# MC1322x register map
Registers are 32-bit, access not given, no defined reset value unless marked. A register's access mark holds for its fields unless they carry their own. Addresses are absolute; registers are grouped by the start of their names; [hi:lo] are bit positions; {n}, {i} and the like mark numbered series.

## TMR3
0x80007060 TMR3_COMPARISON_VALUE_1_[60]_<15:0> 16-bit
0x80007062 TMR3_COMPARISON_VALUE_2_[62]_<15:0> 16-bit
0x80007064 TMR3_CAPTURE_VALUE_[64]_<15:0> 16-bit
0x80007066 TMR3_LOAD_VALUE_[66]_<15:0> 16-bit
0x80007068 TMR3_HOLD_VALUE_[68]_<15:0> 16-bit
0x8000706A TMR3_COUNTER_[6A]_<15:0> 16-bit
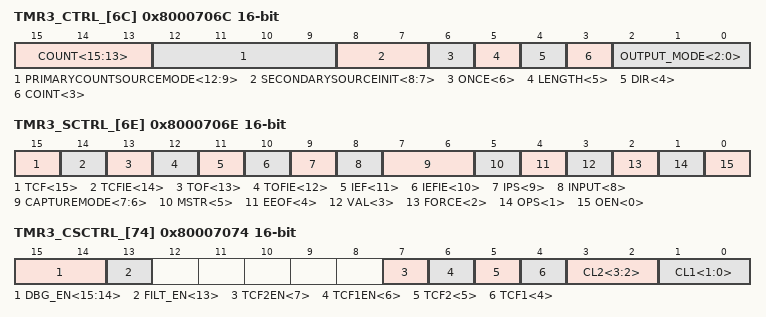
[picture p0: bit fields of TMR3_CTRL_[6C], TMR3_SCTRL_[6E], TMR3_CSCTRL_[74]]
0x8000706C TMR3_CTRL_[6C] 16-bit
  [15:13] COUNT<15:13>, [12:9] PRIMARYCOUNTSOURCEMODE<12:9>, [8:7] SECONDARYSOURCEINIT<8:7>, [6] ONCE<6>, [5] LENGTH<5>, [4] DIR<4>, [3] COINT<3>, [2:0] OUTPUT_MODE<2:0>
0x8000706E TMR3_SCTRL_[6E] 16-bit
  [15] TCF<15>, [14] TCFIE<14>, [13] TOF<13>, [12] TOFIE<12>, [11] IEF<11>, [10] IEFIE<10>, [9] IPS<9>, [8] INPUT<8>, [7:6] CAPTUREMODE<7:6>, [5] MSTR<5>, [4] EEOF<4>, [3] VAL<3>, [2] FORCE<2>, [1] OPS<1>, [0] OEN<0>
0x80007070 TMR3_COMPARATOR_LOAD_1_[70]_<15:0> 16-bit
0x80007072 TMR3_COMPARATOR_LOAD_2_[72]_<15:0> 16-bit
0x80007074 TMR3_CSCTRL_[74] 16-bit
  [15:14] DBG_EN<15:14>, [13] FILT_EN<13>, [7] TCF2EN<7>, [6] TCF1EN<6>, [5] TCF2<5>, [4] TCF1<4>, [3:2] CL2<3:2>, [1:0] CL1<1:0>

## ASM
{0x80008000+4i} ASM_KEY{i}_[{4i:02}] (i=0..2)
0x8000800C ASM_KEY3_[0C]
{0x80008010+4i} ASM_DATA{i}_[{4i+10}] (i=0..2)
0x8000801C ASM_DATA3_[1C]
{0x80008020+4i} ASM_CTR{i}_[{4i+20}] (i=0..2)
0x8000802C ASM_CTR3_[2C]
{0x80008030+4i} ASM_CTR_RSLT_{i}_[{4i+30}] (i=0..2)
0x8000803C ASM_CTR_RSLT_3_[3C]
{0x80008040+4i} ASM_CBC_RSLT_{i}_[{4i+40}] (i=0..2)
0x8000804C ASM_CBC_RSLT_3_[4C]
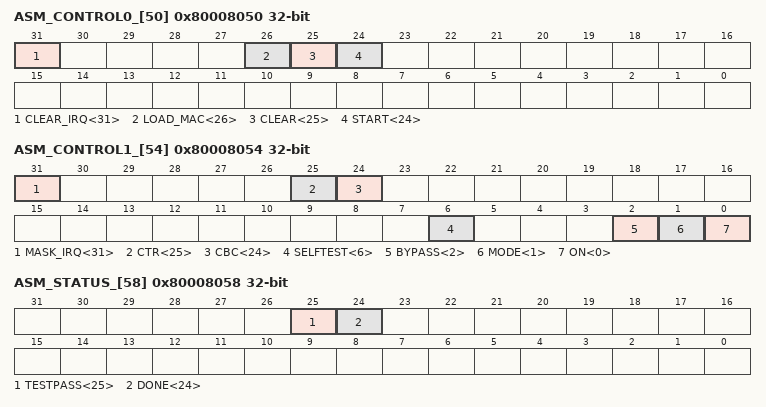
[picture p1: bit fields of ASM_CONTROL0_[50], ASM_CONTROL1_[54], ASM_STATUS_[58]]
0x80008050 ASM_CONTROL0_[50]
  [31] CLEAR_IRQ<31>, [26] LOAD_MAC<26>, [25] CLEAR<25>, [24] START<24>
0x80008054 ASM_CONTROL1_[54]
  [31] MASK_IRQ<31>, [25] CTR<25>, [24] CBC<24>, [6] SELFTEST<6>, [2] BYPASS<2>, [1] MODE<1>, [0] ON<0>
0x80008058 ASM_STATUS_[58]
  [25] TESTPASS<25>, [24] DONE<24>
{0x80008060+4i} ASM_MAC{i}_[{4i+60}] (i=0..2)
0x8000806C ASM_MAC3_[6C]

## UART2
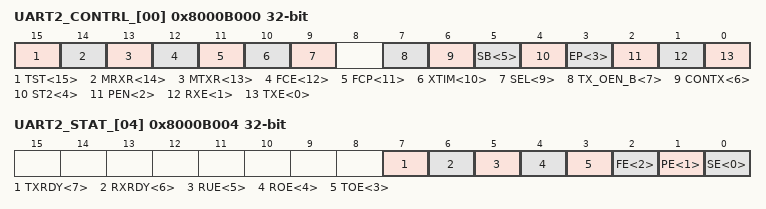
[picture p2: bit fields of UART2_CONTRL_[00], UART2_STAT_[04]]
0x8000B000 UART2_CONTRL_[00]
  [15] TST<15>, [14] MRXR<14>, [13] MTXR<13>, [12] FCE<12>, [11] FCP<11>, [10] XTIM<10>, [9] SEL<9>, [7] TX_OEN_B<7>, [6] CONTX<6>, [5] SB<5>, [4] ST2<4>, [3] EP<3>, [2] PEN<2>, [1] RXE<1>, [0] TXE<0>
0x8000B004 UART2_STAT_[04]
  [7] TXRDY<7>, [6] RXRDY<6>, [5] RUE<5>, [4] ROE<4>, [3] TOE<3>, [2] FE<2>, [1] PE<1>, [0] SE<0>
0x8000B008 UART2_TRX_DATA_[08]_<7:0>
0x8000B00C UART2_RXLEVEL_[0C]_<5:0>
0x8000B010 UART2_TXLEVEL_[10]_<5:0>
0x8000B014 UART2_CTS_LEVEL_[14]_<4:0>
0x8000B018 UART2_BAUD_RATE_DIV_[18]
  [15:0] UBRMOD<15:0>, [15:0] UBRINC<15:0>

## SPIF
0x8000C000 SPIF_TX_DATA_[00]_<31:0>
0x8000C004 SPIF_RX_DATA_[04]_<31:0>
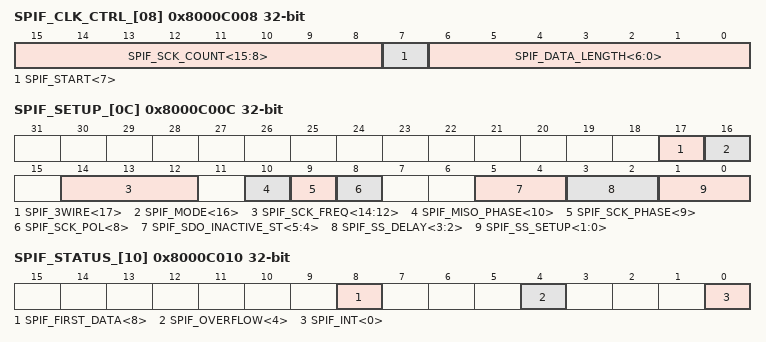
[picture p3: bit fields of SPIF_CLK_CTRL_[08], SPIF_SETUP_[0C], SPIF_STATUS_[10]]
0x8000C008 SPIF_CLK_CTRL_[08]
  [15:8] SPIF_SCK_COUNT<15:8>, [7] SPIF_START<7>, [6:0] SPIF_DATA_LENGTH<6:0>
0x8000C00C SPIF_SETUP_[0C]
  [17] SPIF_3WIRE<17>, [16] SPIF_MODE<16>, [14:12] SPIF_SCK_FREQ<14:12>, [10] SPIF_MISO_PHASE<10>, [9] SPIF_SCK_PHASE<9>, [8] SPIF_SCK_POL<8>, [5:4] SPIF_SDO_INACTIVE_ST<5:4>, [3:2] SPIF_SS_DELAY<3:2>, [1:0] SPIF_SS_SETUP<1:0>
0x8000C010 SPIF_STATUS_[10]
  [8] SPIF_FIRST_DATA<8>, [4] SPIF_OVERFLOW<4>, [0] SPIF_INT<0>

## ADC
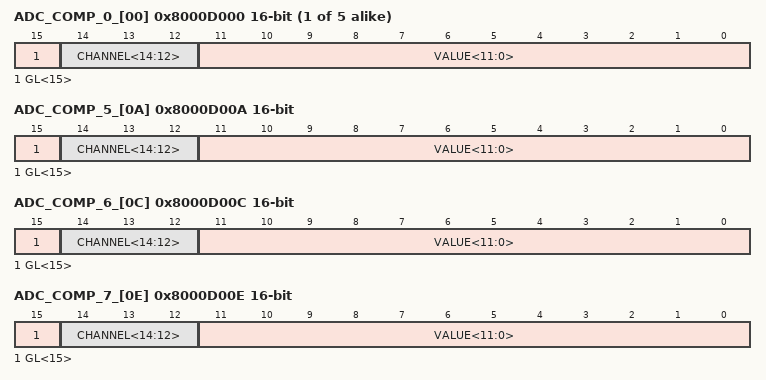
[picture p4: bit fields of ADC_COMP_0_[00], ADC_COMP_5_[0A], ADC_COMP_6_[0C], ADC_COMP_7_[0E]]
{0x8000D000+2i} ADC_COMP_{i}_[{2i:02}] 16-bit (i=0..4)
  [15] GL<15>, [14:12] CHANNEL<14:12>, [11:0] VALUE<11:0>
0x8000D00A ADC_COMP_5_[0A] 16-bit
  [15] GL<15>, [14:12] CHANNEL<14:12>, [11:0] VALUE<11:0>
0x8000D00C ADC_COMP_6_[0C] 16-bit
  [15] GL<15>, [14:12] CHANNEL<14:12>, [11:0] VALUE<11:0>
0x8000D00E ADC_COMP_7_[0E] 16-bit
  [15] GL<15>, [14:12] CHANNEL<14:12>, [11:0] VALUE<11:0>
0x8000D010 ADC_BAT_COMP_OVER_[10]_<11:0> 16-bit
0x8000D012 ADC_BAT_COM_UNDER_[12]_<11:0> 16-bit
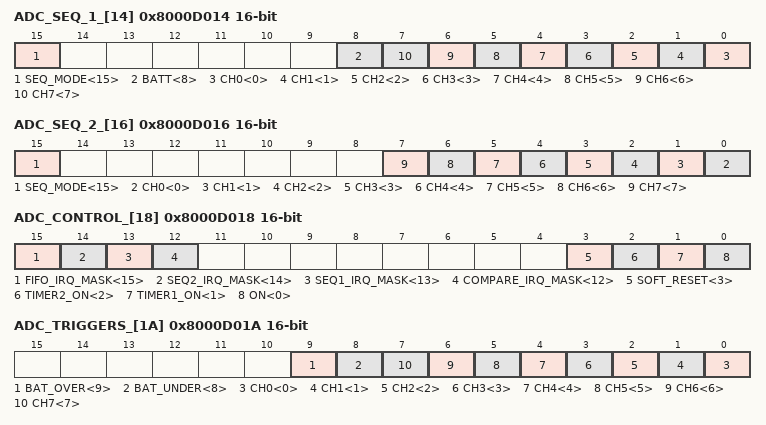
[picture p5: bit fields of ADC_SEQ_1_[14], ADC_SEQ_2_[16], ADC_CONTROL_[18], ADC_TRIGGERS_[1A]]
0x8000D014 ADC_SEQ_1_[14] 16-bit
  [15] SEQ_MODE<15>, [8] BATT<8>, [n] CH{n}<{n}> (n=0..7)
0x8000D016 ADC_SEQ_2_[16] 16-bit
  [15] SEQ_MODE<15>, [n] CH{n}<{n}> (n=0..7)
0x8000D018 ADC_CONTROL_[18] 16-bit
  [15] FIFO_IRQ_MASK<15>, [14] SEQ2_IRQ_MASK<14>, [13] SEQ1_IRQ_MASK<13>, [12] COMPARE_IRQ_MASK<12>, [3] SOFT_RESET<3>, [2] TIMER2_ON<2>, [1] TIMER1_ON<1>, [0] ON<0>
0x8000D01A ADC_TRIGGERS_[1A] 16-bit
  [9] BAT_OVER<9>, [8] BAT_UNDER<8>, [n] CH{n}<{n}> (n=0..7)
0x8000D01C ADC_PRESCALE_[1C]_<7:0> 16-bit
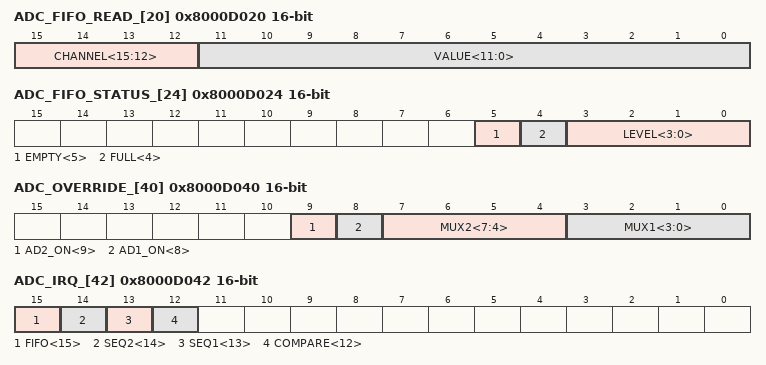
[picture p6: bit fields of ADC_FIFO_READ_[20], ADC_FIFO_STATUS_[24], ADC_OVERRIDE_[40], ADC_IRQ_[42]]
0x8000D020 ADC_FIFO_READ_[20] 16-bit
  [15:12] CHANNEL<15:12>, [11:0] VALUE<11:0>
0x8000D022 ADC_FIFO_CONTROL_LEVEL_[22]_<3:0> 16-bit
0x8000D024 ADC_FIFO_STATUS_[24] 16-bit
  [5] EMPTY<5>, [4] FULL<4>, [3:0] LEVEL<3:0>
0x8000D030 ADC_SAMPLE_RATE_1_HIGH_[30]_<15:0> 16-bit
0x8000D032 ADC_SAMPLE_RATE_1_LOW_[32]_<15:0> 16-bit
0x8000D034 ADC_SAMPLE_RATE_2_HIGH_[34]_<15:0> 16-bit
0x8000D036 ADC_SAMPLE_RATE_2_LOW_[36]_<15:0> 16-bit
0x8000D038 ADC_ON_TIME_[38]_<15:0> 16-bit
0x8000D03A ADC_CONVERT_TIME_[3A]_<15:0> 16-bit
0x8000D03C ADC_CLOCK_DIVIDER_[3C]_<7:0> 16-bit
0x8000D040 ADC_OVERRIDE_[40] 16-bit
  [9] AD2_ON<9>, [8] AD1_ON<8>, [7:4] MUX2<7:4>, [3:0] MUX1<3:0>
0x8000D042 ADC_IRQ_[42] 16-bit
  [15] FIFO<15>, [14] SEQ2<14>, [13] SEQ1<13>, [12] COMPARE<12>
0x8000D044 ADC_MODE_OVERRIDE_[44]_<0> 16-bit
0x8000D046 ADC_AD1_RESULT_[46]_<11:0> 16-bit
0x8000D048 ADC_AD2_RESULT_[48]_<11:0> 16-bit

## INT
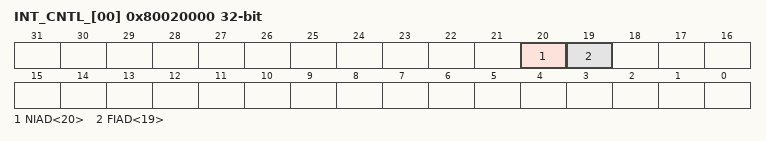
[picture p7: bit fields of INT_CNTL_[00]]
0x80020000 INT_CNTL_[00]
  [20] NIAD<20>, [19] FIAD<19>
0x80020004 INT_NORMAL_MASK_[04]_<4:0>
0x80020008 INT_ENABLE_NUMBER_[08]_<3:0>
0x8002000C INT_DISABLE_NUMBER_[0C]_<3:0>
0x80020010 INT_ENABLE_[10]_<15:0>
0x80020014 INT_TYPE_[14]_<15:0>
0x80020028 INT_NORMAL_VECTOR_[28]_<31:0>
0x8002002C INT_FAST_VECTOR_[2C]_<31:0>
0x80020030 INT_SOURCE_[30]_<15:0>
0x80020034 INT_FORCE_[34]_<15:0>
0x80020038 INT_NORMAL_INT_PENDING_[38]_<15:0>
0x8002003C INT_FAST_INT_PENDING_[3C]_<15:0>
